# TZ10xx register map
File version: 0.1g
Registers are 32-bit, read-write, reset 0x0 unless marked. A register's access mark holds for its fields unless they carry their own. Offsets are from the block's base; [hi:lo] are bit positions; {n}, {i} and the like mark numbered series; 'fields as' and 'values as' point back to an identical list.

## gconf
Base 0x4004A000
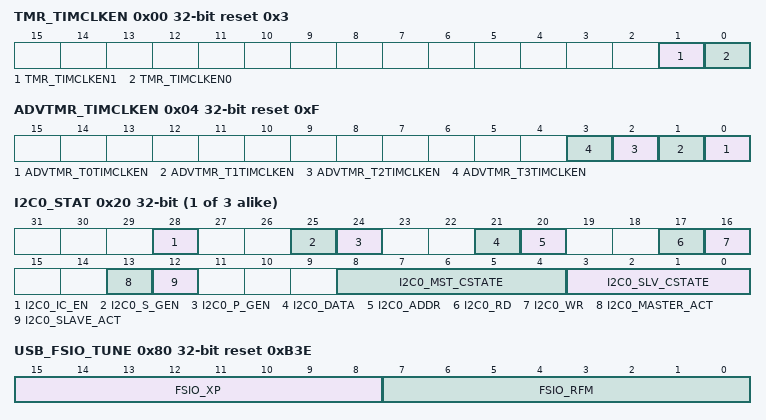
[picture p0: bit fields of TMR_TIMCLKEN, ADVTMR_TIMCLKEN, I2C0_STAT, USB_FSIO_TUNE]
0x00 TMR_TIMCLKEN reset 0x3
  [1] TMR_TIMCLKEN1 — tmr clock enable 1 1: Enable 0: Disable
  [0] TMR_TIMCLKEN0 — tmr clock enable 0 1: Enable 0: Disable
0x04 ADVTMR_TIMCLKEN reset 0xF
  [n] ADVTMR_T{n}TIMCLKEN (n=0..3) — advtmr clock enable {n} 1: Enable 0: Disable
0x10 WDT_WDTCLKEN reset 0x1
  [0] WDT_WDTCLKEN — wdt clock enable 1: Enable 0: Disable
{0x20+4i} I2C{i}_STAT ro (i=0..2)
  [28] I2C{i}_IC_EN — i2c{i} status (i2c enable)
  [25] I2C{i}_S_GEN — i2c{i} status (start condition period)
  [24] I2C{i}_P_GEN — i2c{i} status (stop condition period)
  [21] I2C{i}_DATA — i2c{i} status (data communication period)
  [20] I2C{i}_ADDR — i2c{i} status (address communication period)
  [17] I2C{i}_RD — i2c{i} status (i2c read status)
  [16] I2C{i}_WR — i2c{i} status (i2c write status)
  [13] I2C{i}_MASTER_ACT — i2c{i} status (master active status)
  [12] I2C{i}_SLAVE_ACT — i2c{i} status (slave active status)
  [8:4] I2C{i}_MST_CSTATE — i2c{i} status (master status)
  [3:0] I2C{i}_SLV_CSTATE — i2c{i} status (slave status)
{0x30+4i} SPIM{i}_SLEEP ro reset 0x1 (i=0..3)
  [0] SPIM{i}_SLEEP — spim{i} sleep status 1: Sleep 0: In operation
{0x40+4i} DMACREQ_SEL{i} reset 0x3F (i=0..2)
  [5:0] DMACREQ_SEL{i} — DMAC request signal selection (ch{i}) dma_req, dma_single, dma_ack: Set in the range of 0 to 35. dma_finish: Set in the range of 24 to 31. In any setting value other than above, the request signal (dma_req, dma_single) and response signal (dma_ack, dma_finish) cannot be used.
0x4C DMACREQ_SEL3 reset 0x3F
  [5:0] DMACREQ_SEL3 — DMAC request signal selection (ch3) dma_req, dma_single, dma_ack: Set in the range of 0 to 35. dma_finish: Set in the range of 24 to 31. In any setting value other than above, the request signal (dma_req , dma_single) and response signal (dma_ack,dma_finish) cannot be used.
{0x40+4i} DMACREQ_SEL{i} reset 0x3F (i=4..7)
  fields as DMACREQ_SEL0
0x80 USB_FSIO_TUNE reset 0xB3E
  [15:8] FSIO_XP — USB FSIO Tr/T adjustment (set our specification value.)
  [7:0] FSIO_RFM — USB FSIO Crosspoint adjustment (set our specification value.)
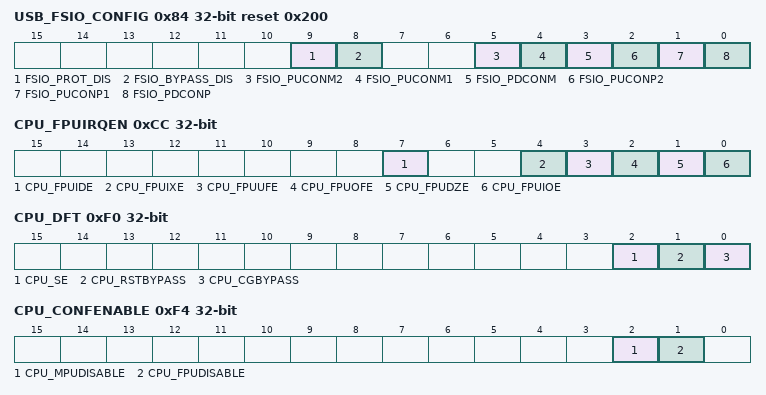
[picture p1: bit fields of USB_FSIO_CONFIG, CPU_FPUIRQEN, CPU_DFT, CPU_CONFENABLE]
0x84 USB_FSIO_CONFIG reset 0x200
  [9] FSIO_PROT_DIS — USB FSIO 5V protect DISABLE (do not change the initial value.)
  [8] FSIO_BYPASS_DIS — USB FSIO series resistance ON (do not change the initial value.)
  [5] FSIO_PUCONM2 — USB FSIO DM terminal Pull-Up setting 2 (do not change the initial value.)
  [4] FSIO_PUCONM1 — USB FSIO DM terminal Pull-Up setting 1 (do not change the initial value.)
  [3] FSIO_PDCONM — USB FSIO DM terminal Pull-Down setting (do not change the initial value.)
  [2] FSIO_PUCONP2 — USB FSIO DP terminal Pull-Up setting 2 (do not change the initial value.)
  [1] FSIO_PUCONP1 — USB FSIO DP terminal Pull-Up setting 1 (do not change the initial value.)
  [0] FSIO_PDCONP — USB FSIO DP terminal Pull-Down setting (do not change the initial value.)
0xC0 CPU_STCALIB
  [25:0] CPU_STCALIB — System Tick calibration CPU [SYST_CALIB] register is set up by this register. [25] : [SYST_CALIB].NOREF [24] : [SYST_CALIB].SKEW [23:0] : [SYST_CALIB].TENMS
0xC4 CPU_TSENABLE
  [0] CPU_TSENABLE — Time Stamp count enable Control of the time stamp counter (48bit) of CPU Trace. It is counted by CPU HCLK. 1 : Count Enable 0 : Count Disable
0xCC CPU_FPUIRQEN
  [7] CPU_FPUIDE — FPU IDC (Input Denormal cumulative) Exception Interrupt Enable 1: Interrupt Enable 0: Interrupt Disable
  [4] CPU_FPUIXE — FPU IXC (Inexact cumulative) Exception Interrupt Enable 1: Interrupt Enable 0: Interrupt Disable
  [3] CPU_FPUUFE — FPU UFC (Underflow cumulative) Exception Interrupt Enable 1: Interrupt Enable 0: Interrupt Disable
  [2] CPU_FPUOFE — FPU OFC (Overflow cumulative) Exception Interrupt Enable 1: Interrupt Enable 0: Interrupt Disable
  [1] CPU_FPUDZE — FPU DZC (Division by Zero cumulative) Exception Interrupt Enable 1: Interrupt Enable 0: Interrupt Disable
  [0] CPU_FPUIOE — FPU IOC(Invalid Operation cumulative) Exception Interrupt Enable 1: Interrupt Enable 0: Interrupt Disable
0xD0 CPU_DEBUGIN reset 0x1
  [0] CPU_DEBUGIN — Debugger detection 1: Enable 0: Disable
0xF0 CPU_DFT
  [2] CPU_SE — Writable when WRITE_PROT=0
  [1] CPU_RSTBYPASS — Writable when WRITE_PROT=0
  [0] CPU_CGBYPASS — Writable when WRITE_PROT=0
0xF4 CPU_CONFENABLE
  [2] CPU_MPUDISABLE — Writable when WRITE_PROT=0
  [1] CPU_FPUDISABLE — Writable when WRITE_PROT=0
0xFC CPU_WRITE_PROT reset 0x1
  [31:0] CPU_WRITE_PROT — 32'h4547_c2a3 writing sets WRITE_PROT=1 32'hd123_4744 writing sets WRITE_PROT=0
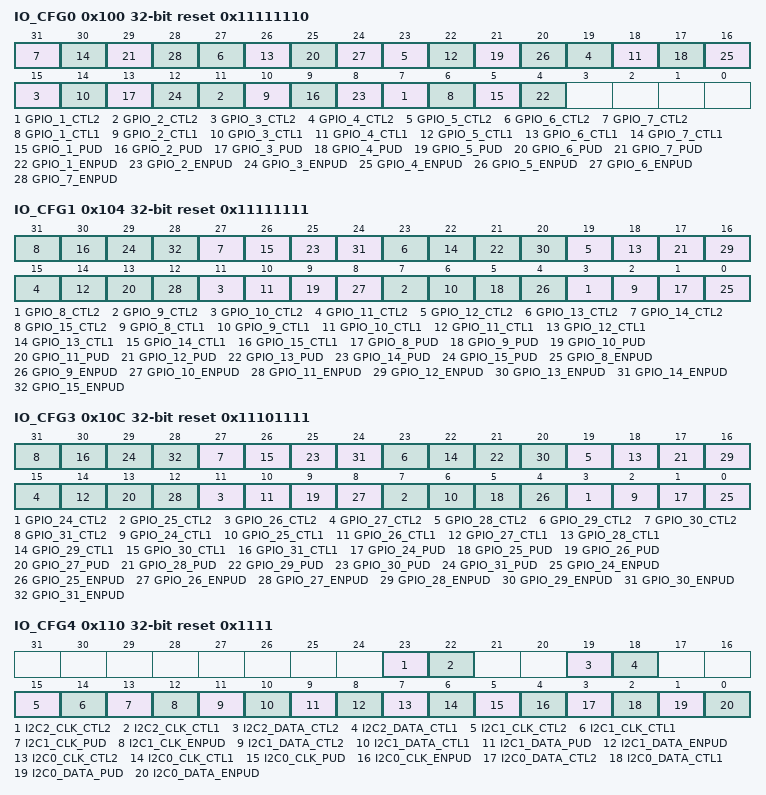
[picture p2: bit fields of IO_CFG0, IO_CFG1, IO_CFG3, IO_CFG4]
0x100 IO_CFG0 reset 0x11111110
  [4n+3] GPIO_{n}_CTL2 (n=1..7) — MCU_GPIO_{n} IO cell CTL2 setting
  [4n+2] GPIO_{n}_CTL1 (n=1..7) — MCU_GPIO_{n} IO cell CTL1 setting
  [4n+1] GPIO_{n}_PUD (n=1..7) — MCU_GPIO_{n} IO cell PUD setting
  [4n] GPIO_{n}_ENPUD (n=1..7) — MCU_GPIO_{n} IO cell ENPUD setting
0x104 IO_CFG1 reset 0x11111111
  [4n-29] GPIO_{n}_CTL2 (n=8..15) — MCU_GPIO_{n} IO cell CTL2 setting
  [4n-30] GPIO_{n}_CTL1 (n=8..15) — MCU_GPIO_{n} IO cell CTL1 setting
  [4n-31] GPIO_{n}_PUD (n=8..15) — MCU_GPIO_{n} IO cell PUD setting
  [4n-32] GPIO_{n}_ENPUD (n=8..15) — MCU_GPIO_{n} IO cell ENPUD setting
0x108 IO_CFG2 ro
0x10C IO_CFG3 reset 0x11101111
  [4n-93] GPIO_{n}_CTL2 (n=24..31) — MCU_GPIO_{n} IO cell CTL2 setting
  [4n-94] GPIO_{n}_CTL1 (n=24..31) — MCU_GPIO_{n} IO cell CTL1 setting
  [4n-95] GPIO_{n}_PUD (n=24..31) — MCU_GPIO_{n} IO cell PUD setting
  [4n-96] GPIO_{n}_ENPUD (n=24..31) — MCU_GPIO_{n} IO cell ENPUD setting
0x110 IO_CFG4 reset 0x1111
  [23] I2C2_CLK_CTL2 — MCU_I2C2_CLK IO cell CTL2 setting
  [22] I2C2_CLK_CTL1 — MCU_I2C2_CLK IO cell CTL1 setting
  [19] I2C2_DATA_CTL2 — MCU_I2C2_DATA IO cell CTL2 setting
  [18] I2C2_DATA_CTL1 — MCU_I2C2_DATA IO cell CTL1 setting
  [15] I2C1_CLK_CTL2 — MCU_I2C1_CLK IO cell CTL2 setting
  [14] I2C1_CLK_CTL1 — MCU_I2C1_CLK IO cell CTL1 setting
  [13] I2C1_CLK_PUD — MCU_I2C1_CLK IO cell PUD setting
  [12] I2C1_CLK_ENPUD — MCU_I2C1_CLK IO cell ENPUD setting
  [11] I2C1_DATA_CTL2 — MCU_I2C1_DATA IO cell CTL2 setting
  [10] I2C1_DATA_CTL1 — MCU_I2C1_DATA IO cell CTL1 setting
  [9] I2C1_DATA_PUD — MCU_I2C1_DATA IO cell PUD setting
  [8] I2C1_DATA_ENPUD — MCU_I2C1_DATA IO cell ENPUD setting
  [7] I2C0_CLK_CTL2 — MCU_I2C0_CLK IO cell CTL2 setting
  [6] I2C0_CLK_CTL1 — MCU_I2C0_CLK IO cell CTL1 setting
  [5] I2C0_CLK_PUD — MCU_I2C0_CLK IO cell PUD setting
  [4] I2C0_CLK_ENPUD — MCU_I2C0_CLK IO cell ENPUD setting
  [3] I2C0_DATA_CTL2 — MCU_I2C0_DATA IO cell CTL2 setting
  [2] I2C0_DATA_CTL1 — MCU_I2C0_DATA IO cell CTL1 setting
  [1] I2C0_DATA_PUD — MCU_I2C0_DATA IO cell PUD setting
  [0] I2C0_DATA_ENPUD — MCU_I2C0_DATA IO cell ENPUD setting
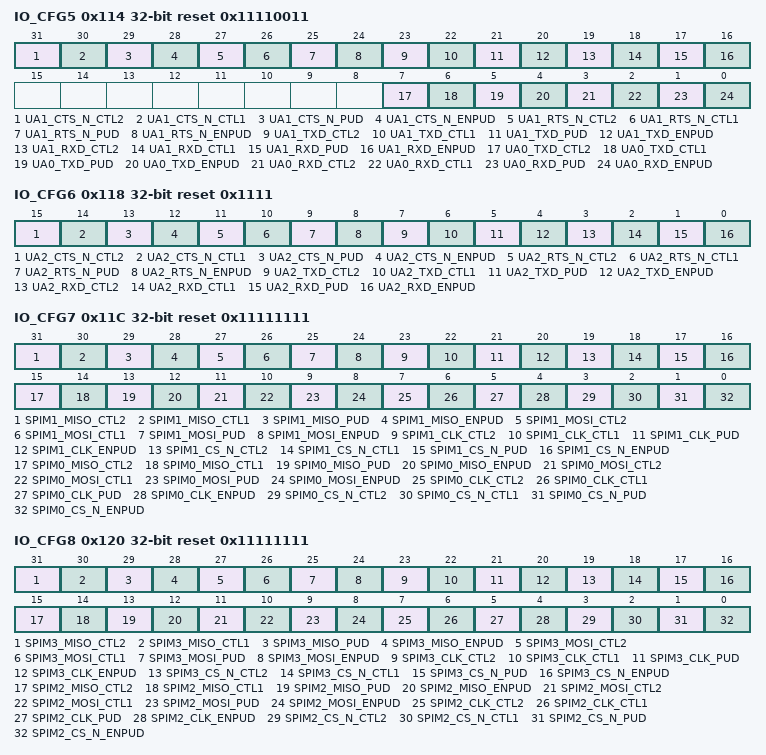
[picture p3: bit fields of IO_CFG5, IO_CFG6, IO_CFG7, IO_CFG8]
0x114 IO_CFG5 reset 0x11110011
  [31] UA1_CTS_N_CTL2 — MCU_UA1_CTS_N IO cell CTL2 setting
  [30] UA1_CTS_N_CTL1 — MCU_UA1_CTS_N IO cell CTL1 setting
  [29] UA1_CTS_N_PUD — MCU_UA1_CTS_N IO cell PUD setting
  [28] UA1_CTS_N_ENPUD — MCU_UA1_CTS_N IO cell ENPUD setting
  [27] UA1_RTS_N_CTL2 — MCU_UA1_RTS_N IO cell CTL2 setting
  [26] UA1_RTS_N_CTL1 — MCU_UA1_RTS_N IO cell CTL1 setting
  [25] UA1_RTS_N_PUD — MCU_UA1_RTS_N IO cell PUD setting
  [24] UA1_RTS_N_ENPUD — MCU_UA1_RTS_N IO cell ENPUD setting
  [23] UA1_TXD_CTL2 — MCU_UA1_TXD IO cell CTL2 setting
  [22] UA1_TXD_CTL1 — MCU_UA1_TXD IO cell CTL1 setting
  [21] UA1_TXD_PUD — MCU_UA1_TXD IO cell PUD setting
  [20] UA1_TXD_ENPUD — MCU_UA1_TXD IO cell ENPUD setting
  [19] UA1_RXD_CTL2 — MCU_UA1_RXD IO cell CTL2 setting
  [18] UA1_RXD_CTL1 — MCU_UA1_RXD IO cell CTL1 setting
  [17] UA1_RXD_PUD — MCU_UA1_RXD IO cell PUD setting
  [16] UA1_RXD_ENPUD — MCU_UA1_RXD IO cell ENPUD setting
  [7] UA0_TXD_CTL2 — MCU_UA0_TXD IO cell CTL2 setting
  [6] UA0_TXD_CTL1 — MCU_UA0_TXD IO cell CTL1 setting
  [5] UA0_TXD_PUD — MCU_UA0_TXD IO cell PUD setting
  [4] UA0_TXD_ENPUD — MCU_UA0_TXD IO cell ENPUD setting
  [3] UA0_RXD_CTL2 — MCU_UA0_RXD IO cell CTL2 setting
  [2] UA0_RXD_CTL1 — MCU_UA0_RXD IO cell CTL1 setting
  [1] UA0_RXD_PUD — MCU_UA0_RXD IO cell PUD setting
  [0] UA0_RXD_ENPUD — MCU_UA0_RXD IO cell ENPUD setting
0x118 IO_CFG6 reset 0x1111
  [15] UA2_CTS_N_CTL2 — MCU_UA2_CTS_N IO cell CTL2 setting
  [14] UA2_CTS_N_CTL1 — MCU_UA2_CTS_N IO cell CTL1 setting
  [13] UA2_CTS_N_PUD — MCU_UA2_CTS_N IO cell PUD setting
  [12] UA2_CTS_N_ENPUD — MCU_UA2_CTS_N IO cell ENPUD setting
  [11] UA2_RTS_N_CTL2 — MCU_UA2_RTS_N IO cell CTL2 setting
  [10] UA2_RTS_N_CTL1 — MCU_UA2_RTS_N IO cell CTL1 setting
  [9] UA2_RTS_N_PUD — MCU_UA2_RTS_N IO cell PUD setting
  [8] UA2_RTS_N_ENPUD — MCU_UA2_RTS_N IO cell ENPUD setting
  [7] UA2_TXD_CTL2 — MCU_UA2_TXD IO cell CTL2 setting
  [6] UA2_TXD_CTL1 — MCU_UA2_TXD IO cell CTL1 setting
  [5] UA2_TXD_PUD — MCU_UA2_TXD IO cell PUD setting
  [4] UA2_TXD_ENPUD — MCU_UA2_TXD IO cell ENPUD setting
  [3] UA2_RXD_CTL2 — MCU_UA2_RXD IO cell CTL2 setting
  [2] UA2_RXD_CTL1 — MCU_UA2_RXD IO cell CTL1 setting
  [1] UA2_RXD_PUD — MCU_UA2_RXD IO cell PUD setting
  [0] UA2_RXD_ENPUD — MCU_UA2_RXD IO cell ENPUD setting
0x11C IO_CFG7 reset 0x11111111
  [31] SPIM1_MISO_CTL2 — MCU_SPIM1_MISO IO cell CTL2 setting
  [30] SPIM1_MISO_CTL1 — MCU_SPIM1_MISO IO cell CTL1 setting
  [29] SPIM1_MISO_PUD — MCU_SPIM1_MISO IO cell PUD setting
  [28] SPIM1_MISO_ENPUD — MCU_SPIM1_MISO IO cell ENPUD setting
  [27] SPIM1_MOSI_CTL2 — MCU_SPIM1_MOSI IO cell CTL2 setting
  [26] SPIM1_MOSI_CTL1 — MCU_SPIM1_MOSI IO cell CTL1 setting
  [25] SPIM1_MOSI_PUD — MCU_SPIM1_MOSI IO cell PUD setting
  [24] SPIM1_MOSI_ENPUD — MCU_SPIM1_MOSI IO cell ENPUD setting
  [23] SPIM1_CLK_CTL2 — MCU_SPIM1_CLK IO cell CTL2 setting
  [22] SPIM1_CLK_CTL1 — MCU_SPIM1_CLK IO cell CTL1 setting
  [21] SPIM1_CLK_PUD — MCU_SPIM1_CLK IO cell PUD setting
  [20] SPIM1_CLK_ENPUD — MCU_SPIM1_CLK IO cell ENPUD setting
  [19] SPIM1_CS_N_CTL2 — MCU_SPIM1_CS_N IO cell CTL2 setting
  [18] SPIM1_CS_N_CTL1 — MCU_SPIM1_CS_N IO cell CTL1 setting
  [17] SPIM1_CS_N_PUD — MCU_SPIM1_CS_N IO cell PUD setting
  [16] SPIM1_CS_N_ENPUD — MCU_SPIM1_CS_N IO cell ENPUD setting
  [15] SPIM0_MISO_CTL2 — MCU_SPIM0_MISO IO cell CTL2 setting
  [14] SPIM0_MISO_CTL1 — MCU_SPIM0_MISO IO cell CTL1 setting
  [13] SPIM0_MISO_PUD — MCU_SPIM0_MISO IO cell PUD setting
  [12] SPIM0_MISO_ENPUD — MCU_SPIM0_MISO IO cell ENPUD setting
  [11] SPIM0_MOSI_CTL2 — MCU_SPIM0_MOSI IO cell CTL2 setting
  [10] SPIM0_MOSI_CTL1 — MCU_SPIM0_MOSI IO cell CTL1 setting
  [9] SPIM0_MOSI_PUD — MCU_SPIM0_MOSI IO cell PUD setting
  [8] SPIM0_MOSI_ENPUD — MCU_SPIM0_MOSI IO cell ENPUD setting
  [7] SPIM0_CLK_CTL2 — MCU_SPIM0_CLK IO cell CTL2 setting
  [6] SPIM0_CLK_CTL1 — MCU_SPIM0_CLK IO cell CTL1 setting
  [5] SPIM0_CLK_PUD — MCU_SPIM0_CLK IO cell PUD setting
  [4] SPIM0_CLK_ENPUD — MCU_SPIM0_CLK IO cell ENPUD setting
  [3] SPIM0_CS_N_CTL2 — MCU_SPIM0_CS_N IO cell CTL2 setting
  [2] SPIM0_CS_N_CTL1 — MCU_SPIM0_CS_N IO cell CTL1 setting
  [1] SPIM0_CS_N_PUD — MCU_SPIM0_CS_N IO cell PUD setting
  [0] SPIM0_CS_N_ENPUD — MCU_SPIM0_CS_N IO cell ENPUD setting
0x120 IO_CFG8 reset 0x11111111
  [31] SPIM3_MISO_CTL2 — MCU_SPIM3_MISO IO cell CTL2 setting
  [30] SPIM3_MISO_CTL1 — MCU_SPIM3_MISO IO cell CTL1 setting
  [29] SPIM3_MISO_PUD — MCU_SPIM3_MISO IO cell PUD setting
  [28] SPIM3_MISO_ENPUD — MCU_SPIM3_MISO IO cell ENPUD setting
  [27] SPIM3_MOSI_CTL2 — MCU_SPIM3_MOSI IO cell CTL2 setting
  [26] SPIM3_MOSI_CTL1 — MCU_SPIM3_MOSI IO cell CTL1 setting
  [25] SPIM3_MOSI_PUD — MCU_SPIM3_MOSI IO cell PUD setting
  [24] SPIM3_MOSI_ENPUD — MCU_SPIM3_MOSI IO cell ENPUD setting
  [23] SPIM3_CLK_CTL2 — MCU_SPIM3_CLK IO cell CTL2 setting
  [22] SPIM3_CLK_CTL1 — MCU_SPIM3_CLK IO cell CTL1 setting
  [21] SPIM3_CLK_PUD — MCU_SPIM3_CLK IO cell PUD setting
  [20] SPIM3_CLK_ENPUD — MCU_SPIM3_CLK IO cell ENPUD setting
  [19] SPIM3_CS_N_CTL2 — MCU_SPIM3_CS_N IO cell CTL2 setting
  [18] SPIM3_CS_N_CTL1 — MCU_SPIM3_CS_N IO cell CTL1 setting
  [17] SPIM3_CS_N_PUD — MCU_SPIM3_CS_N IO cell PUD setting
  [16] SPIM3_CS_N_ENPUD — MCU_SPIM3_CS_N IO cell ENPUD setting
  [15] SPIM2_MISO_CTL2 — MCU_SPIM2_MISO IO cell CTL2 setting
  [14] SPIM2_MISO_CTL1 — MCU_SPIM2_MISO IO cell CTL1 setting
  [13] SPIM2_MISO_PUD — MCU_SPIM2_MISO IO cell PUD setting
  [12] SPIM2_MISO_ENPUD — MCU_SPIM2_MISO IO cell ENPUD setting
  [11] SPIM2_MOSI_CTL2 — MCU_SPIM2_MOSI IO cell CTL2 setting
  [10] SPIM2_MOSI_CTL1 — MCU_SPIM2_MOSI IO cell CTL1 setting
  [9] SPIM2_MOSI_PUD — MCU_SPIM2_MOSI IO cell PUD setting
  [8] SPIM2_MOSI_ENPUD — MCU_SPIM2_MOSI IO cell ENPUD setting
  [7] SPIM2_CLK_CTL2 — MCU_SPIM2_CLK IO cell CTL2 setting
  [6] SPIM2_CLK_CTL1 — MCU_SPIM2_CLK IO cell CTL1 setting
  [5] SPIM2_CLK_PUD — MCU_SPIM2_CLK IO cell PUD setting
  [4] SPIM2_CLK_ENPUD — MCU_SPIM2_CLK IO cell ENPUD setting
  [3] SPIM2_CS_N_CTL2 — MCU_SPIM2_CS_N IO cell CTL2 setting
  [2] SPIM2_CS_N_CTL1 — MCU_SPIM2_CS_N IO cell CTL1 setting
  [1] SPIM2_CS_N_PUD — MCU_SPIM2_CS_N IO cell PUD setting
  [0] SPIM2_CS_N_ENPUD — MCU_SPIM2_CS_N IO cell ENPUD setting
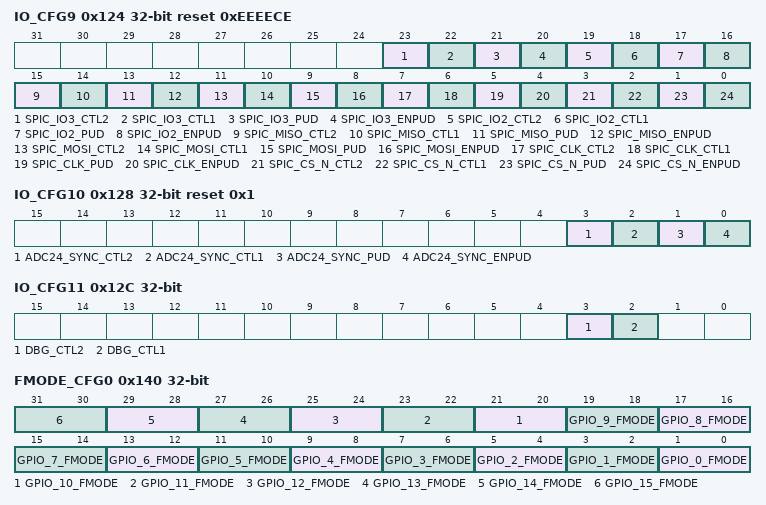
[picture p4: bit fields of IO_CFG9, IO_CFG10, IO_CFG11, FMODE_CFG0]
0x124 IO_CFG9 reset 0xEEEECE
  [23] SPIC_IO3_CTL2 — MCU_SPIC_IO3 IO cell CTL2 setting
  [22] SPIC_IO3_CTL1 — MCU_SPIC_IO3 IO cell CTL1 setting
  [21] SPIC_IO3_PUD — MCU_SPIC_IO3 IO cell PUD setting
  [20] SPIC_IO3_ENPUD — MCU_SPIC_IO3 IO cell ENPUD setting
  [19] SPIC_IO2_CTL2 — MCU_SPIC_IO2 IO cell CTL2 setting
  [18] SPIC_IO2_CTL1 — MCU_SPIC_IO2 IO cell CTL1 setting
  [17] SPIC_IO2_PUD — MCU_SPIC_IO2 IO cell PUD setting
  [16] SPIC_IO2_ENPUD — MCU_SPIC_IO2 IO cell ENPUD setting
  [15] SPIC_MISO_CTL2 — MCU_SPIC_MISO IO cell CTL2 setting
  [14] SPIC_MISO_CTL1 — MCU_SPIC_MISO IO cell CTL1 setting
  [13] SPIC_MISO_PUD — MCU_SPIC_MISO IO cell PUD setting
  [12] SPIC_MISO_ENPUD — MCU_SPIC_MISO IO cell ENPUD setting
  [11] SPIC_MOSI_CTL2 — MCU_SPIC_MOSI IO cell CTL2 setting
  [10] SPIC_MOSI_CTL1 — MCU_SPIC_MOSI IO cell CTL1 setting
  [9] SPIC_MOSI_PUD — MCU_SPIC_MOSI IO cell PUD setting
  [8] SPIC_MOSI_ENPUD — MCU_SPIC_MOSI IO cell ENPUD setting
  [7] SPIC_CLK_CTL2 — MCU_SPIC_CLK IO cell CTL2 setting
  [6] SPIC_CLK_CTL1 — MCU_SPIC_CLK IO cell CTL1 setting
  [5] SPIC_CLK_PUD — MCU_SPIC_CLK IO cell PUD setting
  [4] SPIC_CLK_ENPUD — MCU_SPIC_CLK IO cell ENPUD setting
  [3] SPIC_CS_N_CTL2 — MCU_SPIC_CS_N IO cell CTL2 setting
  [2] SPIC_CS_N_CTL1 — MCU_SPIC_CS_N IO cell CTL1 setting
  [1] SPIC_CS_N_PUD — MCU_SPIC_CS_N IO cell PUD setting
  [0] SPIC_CS_N_ENPUD — MCU_SPIC_CS_N IO cell ENPUD setting
0x128 IO_CFG10 reset 0x1
  [3] ADC24_SYNC_CTL2 — MCU_ADC24_SYNC IO cell CTL2 setting
  [2] ADC24_SYNC_CTL1 — MCU_ADC24_SYNC IO cell CTL1 setting
  [1] ADC24_SYNC_PUD — MCU_ADC24_SYNC IO cell PUD setting
  [0] ADC24_SYNC_ENPUD — MCU_ADC24_SYNC IO cell ENPUD setting
0x12C IO_CFG11
  [3] DBG_CTL2 — MCU_DBG_* IO cell CTL2 setting
  [2] DBG_CTL1 — MCU_DBG_* IO cell CTL1 setting
0x140 FMODE_CFG0 — For details on Function Mode, see "Datasheet Summary 5.1 Setting Multiple function I/O".
  [2n+1:2n] GPIO_{n}_FMODE (n=0..15) — MCU_GPIO_{n} Function Mode setting
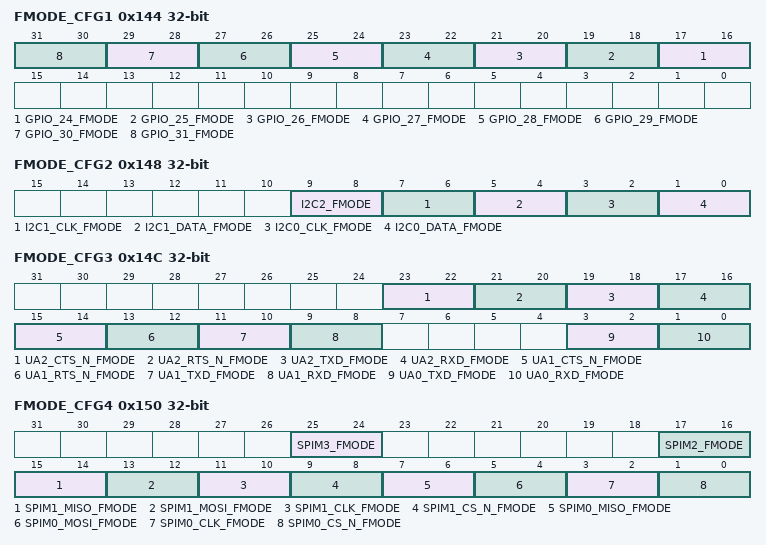
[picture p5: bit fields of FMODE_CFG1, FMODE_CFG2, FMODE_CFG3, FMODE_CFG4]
0x144 FMODE_CFG1 — For details on Function Mode, see "Datasheet Summary 5.1 Setting Multiple function I/O".
  [2n-31:2n-32] GPIO_{n}_FMODE (n=24..31) — MCU_GPIO_{n} Function Mode setting
0x148 FMODE_CFG2 — For details on Function Mode, see "Datasheet Summary 5.1 Setting Multiple function I/O".
  [9:8] I2C2_FMODE — MCU_I2C2_* Function Mode setting
  [7:6] I2C1_CLK_FMODE — MCU_I2C1_CLK Function Mode setting
  [5:4] I2C1_DATA_FMODE — MCU_I2C1_DATA Function Mode setting
  [3:2] I2C0_CLK_FMODE — MCU_I2C0_CLK Function Mode setting
  [1:0] I2C0_DATA_FMODE — MCU_I2C0_DATA Function Mode setting
0x14C FMODE_CFG3 — For details on Function Mode, see "Datasheet Summary 5.1 Setting Multiple function I/O".
  [23:22] UA2_CTS_N_FMODE — MCU_UA2_CTS_N Function Mode setting
  [21:20] UA2_RTS_N_FMODE — MCU_UA2_RTS_N Function Mode setting
  [19:18] UA2_TXD_FMODE — MCU_UA2_TXD Function Mode setting
  [17:16] UA2_RXD_FMODE — MCU_UA2_RXD Function Mode setting
  [15:14] UA1_CTS_N_FMODE — MCU_UA1_CTS_N Function Mode setting
  [13:12] UA1_RTS_N_FMODE — MCU_UA1_RTS_N Function Mode setting
  [11:10] UA1_TXD_FMODE — MCU_UA1_TXD Function Mode setting
  [9:8] UA1_RXD_FMODE — MCU_UA1_RXD Function Mode setting
  [3:2] UA0_TXD_FMODE — MCU_UA0_TXD Function Mode setting
  [1:0] UA0_RXD_FMODE — MCU_UA0_RXD Function Mode setting
0x150 FMODE_CFG4 — For details on Function Mode, see "Datasheet Summary 5.1 Setting Multiple function I/O".
  [25:24] SPIM3_FMODE — MCU_SPIM3_* Function Mode setting
  [17:16] SPIM2_FMODE — MCU_SPIM2_* Function Mode setting
  [15:14] SPIM1_MISO_FMODE — MCU_SPIM1_MISO Function Mode setting
  [13:12] SPIM1_MOSI_FMODE — MCU_SPIM1_MOSI Function Mode setting
  [11:10] SPIM1_CLK_FMODE — MCU_SPIM1_CLK Function Mode setting
  [9:8] SPIM1_CS_N_FMODE — MCU_SPIM1_CS_N Function Mode setting
  [7:6] SPIM0_MISO_FMODE — MCU_SPIM0_MISO Function Mode setting
  [5:4] SPIM0_MOSI_FMODE — MCU_SPIM0_MOSI Function Mode setting
  [3:2] SPIM0_CLK_FMODE — MCU_SPIM0_CLK Function Mode setting
  [1:0] SPIM0_CS_N_FMODE — MCU_SPIM0_CS_N Function Mode setting
0x154 FMODE_CFG5 — For details on Function Mode, see "Datasheet Summary 5.1 Setting Multiple function I/O".
  [1:0] SPIC_FMODE — MCU_SPIC_* Function Mode setting
0x158 FMODE_CFG6 — For details on Function Mode, see "Datasheet Summary 5.1 Setting Multiple function I/O".
  [1:0] ADC24_SYNC_FMODE — MCU_ADC24_SYNC Function Mode setting
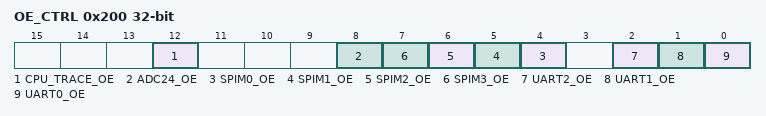
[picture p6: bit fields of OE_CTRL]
0x200 OE_CTRL
  [12] CPU_TRACE_OE — Output Enable for CPU Trace signals 1 : Output Enable 0 : Output Disable
  [8] ADC24_OE — Output Enable for ASC24 signals 1 : Output Enable 0 : Output Disable
  [n+4] SPIM{n}_OE (n=0..3) — Output Enable for SPIM{n} signals 1 : Output Enable 0 : Output Disable
  [2] UART2_OE — Output Enable for UART2 signals 1 : Output Enable 0 : Output Disable
  [1] UART1_OE — Output Enable for UART1 signals 1 : Output Enable 0 : Output Disable
  [0] UART0_OE — Output Enable for UART0 signals 1 : Output Enable 0 : Output Disable
